# ecap register map
Vendor: Texas Instruments
Peripheral module from a debugger description file (folder am335x).
Registers are 32-bit, read-write, no defined reset value unless marked. A register's access mark holds for its fields unless they carry their own. Offsets are as the file gives them; lines under a group give offsets from that group; [hi:lo] are bit positions; {n}, {i} and the like mark numbered series; 'fields as' and 'values as' point back to an identical list; <NAME> marks a mode.

## ECAP
0x00 TSCTR
  [31:0] TSCTR — Active 32 bit counter register that is used as the capture time-base
0x04 CTRPHS
  [31:0] CTRPHS — Counter phase value register that can be programmed for phase lag/lead. This register shadows TSCTR and is loaded into TSCTR upon either a SYNCI event or S/W force via a control bit. Used to achieve phase control synchronization with respect to other eCAP and EPWM time-bases.
0x08 CAP1
  [31:0] CAP1 — This register can be loaded (written) by the following. (a) Time-Stamp (that is, counter value) during a capture event. (b) Software may be useful for test purposes. (c) APRD active register when used in APWM mode.
0x0C CAP2
  [31:0] CAP2 — This register can be loaded (written) by the following. (a) Time-Stamp (that is, counter value) during a capture event. (b) Software may be useful for test purposes. (c) APRD active register when used in APWM mode.
0x10 CAP3
  [31:0] CAP3 — In CMP mode, this is a time-stamp capture register. In APWM mode, this is the period shadow (APRD) register. You update the PWM period value through this register. In this mode, CAP3 shadows CAP1.
0x14 CAP4
  [31:0] CAP4 — In CMP mode, this is a time-stamp capture register. In APWM mode, this is the compare shadow (ACMP) register. You update the PWM compare value through this register. In this mode, CAP4 shadows CAP2.
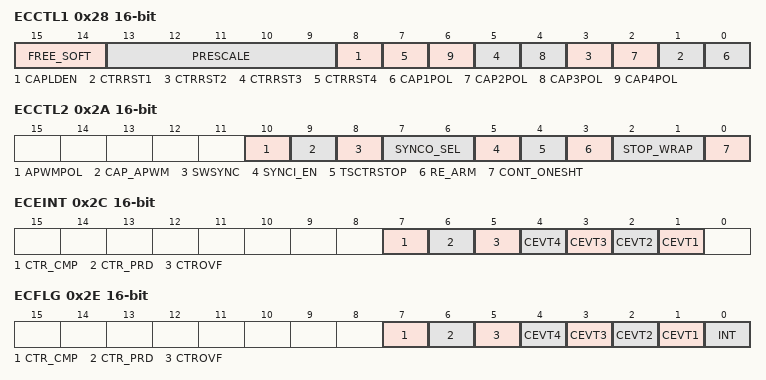
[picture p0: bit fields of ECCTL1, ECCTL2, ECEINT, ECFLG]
0x28 ECCTL1 16-bit
  [15:14] FREE_SOFT — Emulation Control
  [13:9] PRESCALE — Event Filter prescale select ...
  [8] CAPLDEN — Enable Loading of CAP1 to CAP4 registers on a capture event
  [2n-1] CTRRST{n} (n=1..4) — Counter Reset on Capture Event {n}
  [2n-2] CAP{n}POL (n=1..4) — Capture Event {n} Polarity select
0x2A ECCTL2 16-bit access per field
  [10] APWMPOL rw — APWM output polarity select. This is applicable only in APWM operating mode
  [9] CAP_APWM rw — CAP/APWM operating mode select
  [8] SWSYNC rw — Software-forced Counter (TSCTR) Synchronizing. This provides a convenient software method to synchronize some or all ECAP time bases. In APWM mode, the synchronizing can also be done via the CTR = PRD event. Note: Selection CTR = PRD is meaningful only in APWM mode. However, you can choose it in CAP mode if you find doing so useful.
  [7:6] SYNCO_SEL rw — Sync-Out Select
  [5] SYNCI_EN rw — Counter (TSCTR) Sync-In select mode
  [4] TSCTRSTOP rw — Time Stamp (TSCTR) Counter Stop (freeze) Control
  [3] RE_ARM rw — One-Shot Re-Arming Control, that is, wait for stop trigger. Note: The re-arm function is valid in one shot or continuous mode.
  [2:1] STOP_WRAP rw — Stop value for one-shot mode. This is the number (between 1 and 4) of captures allowed to occur before the CAP (1 through 4) registers are frozen, that is, capture sequence is stopped. Wrap value for continuous mode. This is the number (between 1 and 4) of the capture register in which the circular buffer wraps around and starts again. Notes: STOP_WRAP is compared to Mod4 counter and, when equal, the following two actions occur. (1) Mod4 counter is stopped (frozen). (2) Capture register loads are inhibited. In one-shot mode, further interrupt events are blocked until re-armed.
  [0] CONT_ONESHT rw — Continuous or one-shot mode control (applicable only in capture mode)
0x2C ECEINT 16-bit access per field — The interrupt enable bits (CEVTn) block any of the selected events from generating an interrupt. Events will still be latched into the flag bit (ECFLG register) and can be forced or cleared via the ECFRC and ECCLR registers. The proper procedure for configuring peripheral modes and interrupts is: 1. Disable global interrupts. 2. Stop eCAP counter. 3. Disable eCAP interrupts. 4. Configure peripheral registers. 5. Clear spurious eCAP interrupt flags. 6. Enable eCAP interrupts. 7. Start eCAP counter. 8. Enable global interrupts.
  [7] CTR_CMP rw — Counter Equal Compare Interrupt Enable.
  [6] CTR_PRD rw — Counter Equal Period Interrupt Enable.
  [5] CTROVF rw — Counter Overflow Interrupt Enable.
  [4] CEVT4 rw — Capture Event 4 Interrupt Enable.
  [3] CEVT3 rw — Capture Event 3 Interrupt Enable.
  [2] CEVT2 rw — Capture Event 2 Interrupt Enable.
  [1] CEVT1 rw — Capture Event 1 Interrupt Enable .
0x2E ECFLG 16-bit ro
  [7] CTR_CMP — Compare Equal Compare Status Flag. This flag is only active in APWM mode.
  [6] CTR_PRD — Counter Equal Period Status Flag. This flag is only active in APWM mode.
  [5] CTROVF — Counter Overflow Status Flag. This flag is active in CAP and APWM mode.
  [4] CEVT4 — Capture Event 4 Status Flag This flag is only active in CAP mode.
  [3] CEVT3 — Capture Event 3 Status Flag. This flag is active only in CAP mode.
  [2] CEVT2 — Capture Event 2 Status Flag. This flag is only active in CAP mode.
  [1] CEVT1 — Capture Event 1 Status Flag. This flag is only active in CAP mode.
  [0] INT — Global Interrupt Status Flag
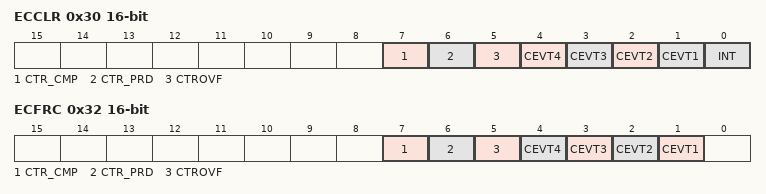
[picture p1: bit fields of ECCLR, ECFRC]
0x30 ECCLR 16-bit access per field
  [7] CTR_CMP rw — Counter Equal Compare Status Flag
  [6] CTR_PRD rw — Counter Equal Period Status Flag
  [5] CTROVF rw — Counter Overflow Status Flag
  [n] CEVT{n} rw (n=1..4) — Capture Event {n} Status Flag
  [0] INT rw — Global Interrupt Clear Flag
0x32 ECFRC 16-bit access per field
  [7] CTR_CMP rw — Force Counter Equal Compare Interrupt
  [6] CTR_PRD rw — Force Counter Equal Period Interrupt
  [5] CTROVF rw — Force Counter Overflow
  [4] CEVT4 rw — Force Capture Event 4
  [3] CEVT3 rw — Force Capture Event 3
  [2] CEVT2 rw — Force Capture Event 2
  [1] CEVT1 rw — Always reads back a 0. Force Capture Event 1
0x5C REVID ro
  [31:0] REV — Revision ID.
